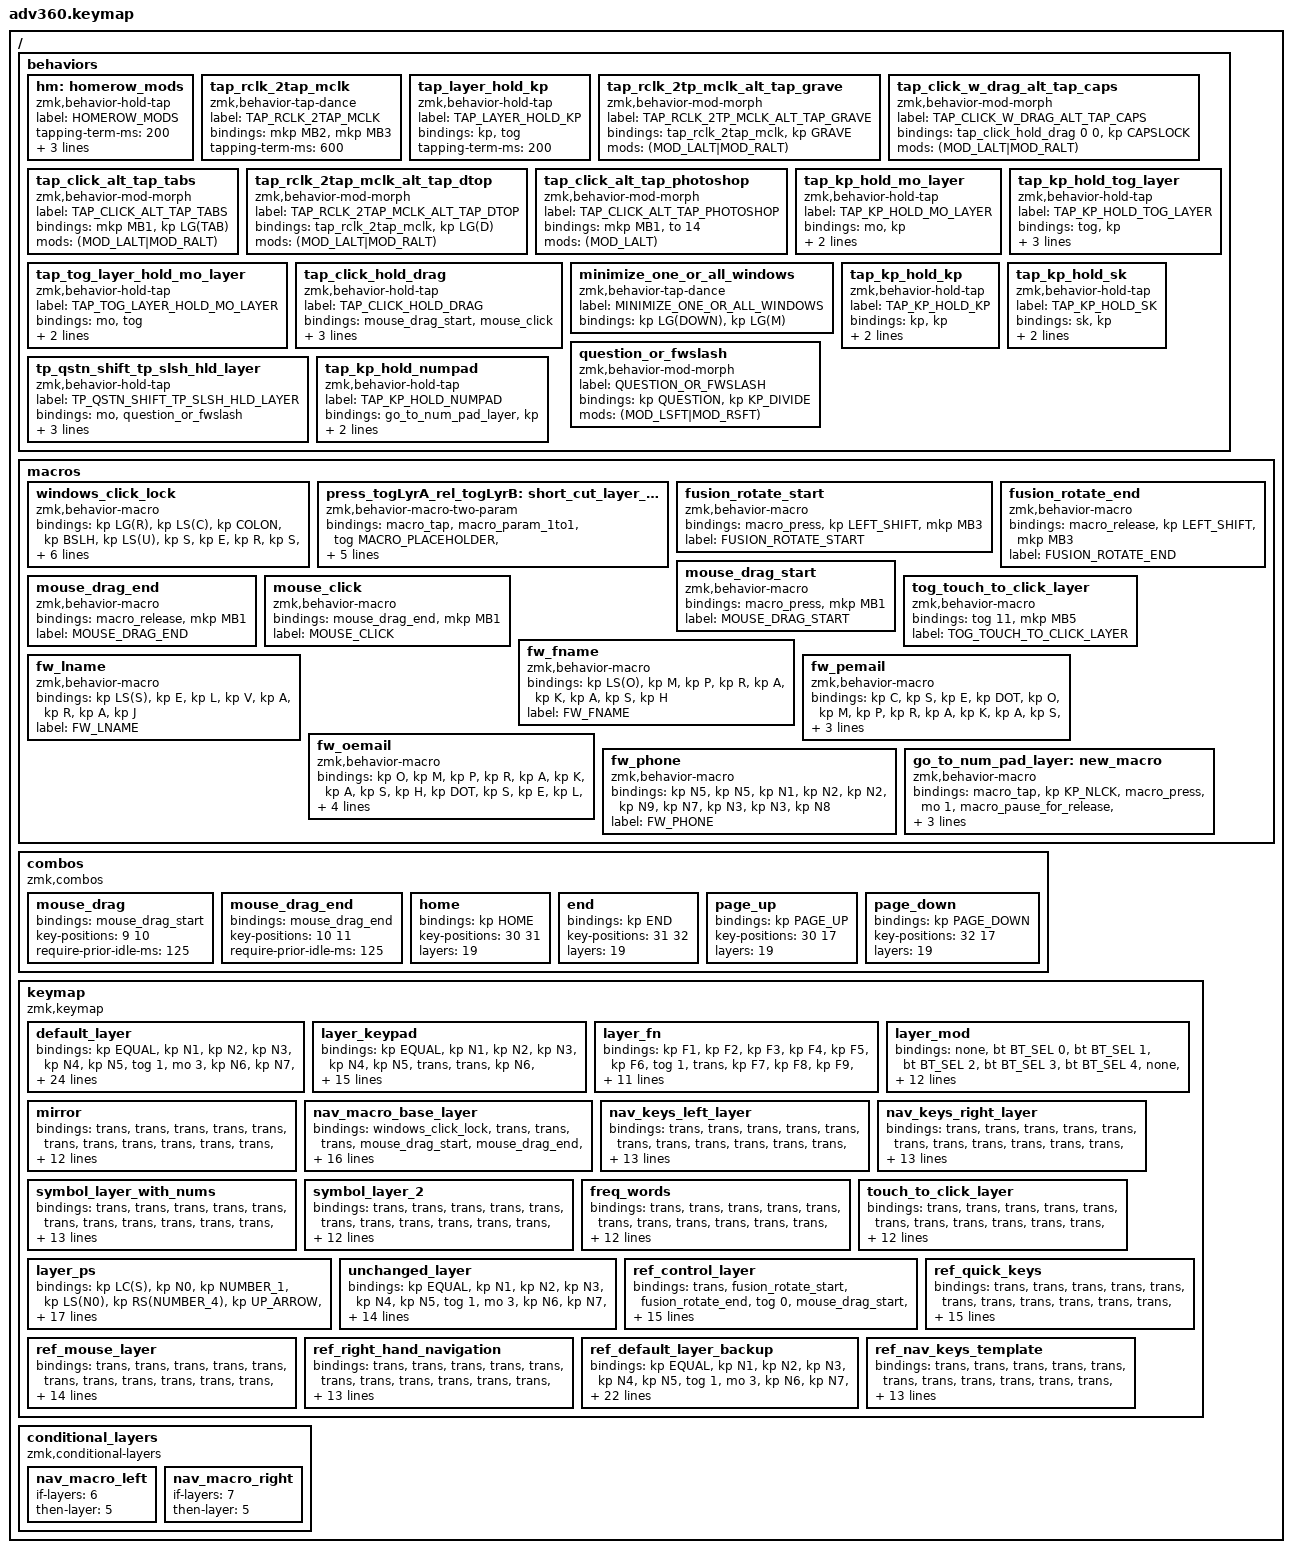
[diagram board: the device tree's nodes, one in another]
/*
 * Copyright (c) 2020 The ZMK Contributors
 *
 * SPDX-License-Identifier: MIT
 */
/* THIS FILE WAS GENERATED!
 *
 * This file was generated automatically. You may or may not want to
 * edit it directly.
 */

#include <dt-bindings/zmk/mouse.h>
#include <behaviors.dtsi>
#include <dt-bindings/zmk/backlight.h>
#include <dt-bindings/zmk/bt.h>
#include <dt-bindings/zmk/keys.h>
#include <dt-bindings/zmk/keys.h>
#include <dt-bindings/zmk/rgb.h>

/ {
    behaviors {
        #include "macros.dtsi"
    #include "version.dtsi"

        hm: homerow_mods {
            compatible = "zmk,behavior-hold-tap";
            label = "HOMEROW_MODS";
            #binding-cells = <2>;
            tapping-term-ms = <200>;
            quick_tap_ms = <175>;
            flavor = "tap-preferred";
            bindings = <&kp>, <&kp>;
        };

        tap_rclk_2tap_mclk: tap_rclk_2tap_mclk {
            compatible = "zmk,behavior-tap-dance";
            label = "TAP_RCLK_2TAP_MCLK";
            #binding-cells = <0>;
            bindings = <&mkp MB2>, <&mkp MB3>;

            tapping-term-ms = <600>;
        };

        tap_layer_hold_kp: tap_layer_hold_kp {
            compatible = "zmk,behavior-hold-tap";
            label = "TAP_LAYER_HOLD_KP";
            bindings = <&kp>, <&tog>;

            #binding-cells = <2>;
            tapping-term-ms = <200>;
        };

        tap_rclk_2tp_mclk_alt_tap_grave: tap_rclk_2tp_mclk_alt_tap_grave {
            compatible = "zmk,behavior-mod-morph";
            label = "TAP_RCLK_2TP_MCLK_ALT_TAP_GRAVE";
            bindings = <&tap_rclk_2tap_mclk>, <&kp GRAVE>;

            #binding-cells = <0>;
            mods = <(MOD_LALT|MOD_RALT)>;
        };

        tap_click_w_drag_alt_tap_caps: tap_click_w_drag_alt_tap_caps {
            compatible = "zmk,behavior-mod-morph";
            label = "TAP_CLICK_W_DRAG_ALT_TAP_CAPS";
            bindings = <&tap_click_hold_drag 0 0>, <&kp CAPSLOCK>;

            #binding-cells = <0>;
            mods = <(MOD_LALT|MOD_RALT)>;
        };

        tap_click_alt_tap_tabs: tap_click_alt_tap_tabs {
            compatible = "zmk,behavior-mod-morph";
            label = "TAP_CLICK_ALT_TAP_TABS";
            bindings = <&mkp MB1>, <&kp LG(TAB)>;

            #binding-cells = <0>;
            mods = <(MOD_LALT|MOD_RALT)>;
        };

        tap_rclk_2tap_mclk_alt_tap_dtop: tap_rclk_2tap_mclk_alt_tap_dtop {
            compatible = "zmk,behavior-mod-morph";
            label = "TAP_RCLK_2TAP_MCLK_ALT_TAP_DTOP";
            bindings = <&tap_rclk_2tap_mclk>, <&kp LG(D)>;

            #binding-cells = <0>;
            mods = <(MOD_LALT|MOD_RALT)>;
        };

        tap_click_alt_tap_photoshop: tap_click_alt_tap_photoshop {
            compatible = "zmk,behavior-mod-morph";
            label = "TAP_CLICK_ALT_TAP_PHOTOSHOP";
            bindings = <&mkp MB1>, <&to 14>;

            #binding-cells = <0>;
            mods = <(MOD_LALT)>;
        };

        tap_kp_hold_mo_layer: tap_kp_hold_mo_layer {
            compatible = "zmk,behavior-hold-tap";
            label = "TAP_KP_HOLD_MO_LAYER";
            bindings = <&mo>, <&kp>;

            #binding-cells = <2>;
            tapping-term-ms = <250>;
            flavor = "tap-preferred";
        };

        tap_kp_hold_tog_layer: tap_kp_hold_tog_layer {
            compatible = "zmk,behavior-hold-tap";
            label = "TAP_KP_HOLD_TOG_LAYER";
            bindings = <&tog>, <&kp>;

            #binding-cells = <2>;
            tapping-term-ms = <700>;
            flavor = "tap-preferred";
            require-prior-idle-ms = <125>;
        };

        tap_tog_layer_hold_mo_layer: tap_tog_layer_hold_mo_layer {
            compatible = "zmk,behavior-hold-tap";
            label = "TAP_TOG_LAYER_HOLD_MO_LAYER";
            bindings = <&mo>, <&tog>;

            #binding-cells = <2>;
            tapping-term-ms = <150>;
            flavor = "tap-preferred";
        };

        tap_click_hold_drag: tap_click_hold_drag {
            compatible = "zmk,behavior-hold-tap";
            label = "TAP_CLICK_HOLD_DRAG";
            bindings = <&mouse_drag_start>, <&mouse_click>;

            #binding-cells = <2>;
            tapping-term-ms = <200>;
            flavor = "tap-preferred";
            require-prior-idle-ms = <125>;
        };

        minimize_one_or_all_windows: minimize_one_or_all_windows {
            compatible = "zmk,behavior-tap-dance";
            label = "MINIMIZE_ONE_OR_ALL_WINDOWS";
            #binding-cells = <0>;
            bindings = <&kp LG(DOWN)>, <&kp LG(M)>;
        };

        tap_kp_hold_kp: tap_kp_hold_kp {
            compatible = "zmk,behavior-hold-tap";
            label = "TAP_KP_HOLD_KP";
            bindings = <&kp>, <&kp>;

            #binding-cells = <2>;
            tapping-term-ms = <250>;
            flavor = "tap-preferred";
        };

        tap_kp_hold_sk: tap_kp_hold_sk {
            compatible = "zmk,behavior-hold-tap";
            label = "TAP_KP_HOLD_SK";
            bindings = <&sk>, <&kp>;

            #binding-cells = <2>;
            tapping-term-ms = <350>;
            flavor = "tap-preferred";
        };

        question_or_fwslash: question_or_fwslash {
            compatible = "zmk,behavior-mod-morph";
            label = "QUESTION_OR_FWSLASH";
            bindings = <&kp QUESTION>, <&kp KP_DIVIDE>;

            #binding-cells = <0>;
            mods = <(MOD_LSFT|MOD_RSFT)>;
        };

        tp_qstn_shift_tp_slsh_hld_layer: tp_qstn_shift_tp_slsh_hld_layer {
            compatible = "zmk,behavior-hold-tap";
            label = "TP_QSTN_SHIFT_TP_SLSH_HLD_LAYER";
            bindings = <&mo>, <&question_or_fwslash>;

            #binding-cells = <2>;
            tapping-term-ms = <700>;
            flavor = "tap-preferred";
            require-prior-idle-ms = <125>;
        };

        tap_kp_hold_numpad: tap_kp_hold_numpad {
            compatible = "zmk,behavior-hold-tap";
            label = "TAP_KP_HOLD_NUMPAD";
            bindings = <&go_to_num_pad_layer>, <&kp>;

            #binding-cells = <2>;
            tapping-term-ms = <250>;
            flavor = "tap-preferred";
        };
    };

    macros {
        windows_click_lock: windows_click_lock {
            compatible = "zmk,behavior-macro";
            #binding-cells = <0>;
            bindings = <&kp LG(R) &kp LS(C) &kp COLON &kp BSLH &kp LS(U) &kp S &kp E &kp R &kp S &kp BSLH &kp O &kp M &kp P &kp R &kp A &kp BSLH &kp LS(D) &kp E &kp S &kp K &kp T &kp O &kp P &kp BSLH &kp C &kp L &kp I &kp C &kp K &kp L &kp O &kp C &kp K &kp DOT &kp V &kp B &kp S &kp ENTER>;
            label = "WINDOWS_CLICK_LOCK";
        };

        press_togLyrA_rel_togLyrB: short_cut_layer_activation {
            compatible = "zmk,behavior-macro-two-param";
            #binding-cells = <2>;
            bindings =
                <&macro_tap>,
                <&macro_param_1to1 &tog MACRO_PLACEHOLDER>,
                <&macro_pause_for_release>,
                <&macro_param_2to1 &tog MACRO_PLACEHOLDER>;

            label = "SHORT_CUT_LAYER_ACTIVATION";
            wait-ms = <1>;
            tap-ms = <1>;
        };

        fusion_rotate_start: fusion_rotate_start {
            compatible = "zmk,behavior-macro";
            #binding-cells = <0>;
            bindings = <&macro_press>, <&kp LEFT_SHIFT &mkp MB3>;

            label = "FUSION_ROTATE_START";
        };

        fusion_rotate_end: fusion_rotate_end {
            compatible = "zmk,behavior-macro";
            #binding-cells = <0>;
            bindings = <&macro_release>, <&kp LEFT_SHIFT &mkp MB3>;

            label = "FUSION_ROTATE_END";
        };

        mouse_drag_start: mouse_drag_start {
            compatible = "zmk,behavior-macro";
            #binding-cells = <0>;
            bindings = <&macro_press>, <&mkp MB1>;

            label = "MOUSE_DRAG_START";
        };

        mouse_drag_end: mouse_drag_end {
            compatible = "zmk,behavior-macro";
            #binding-cells = <0>;
            bindings = <&macro_release>, <&mkp MB1>;

            label = "MOUSE_DRAG_END";
        };

        mouse_click: mouse_click {
            compatible = "zmk,behavior-macro";
            #binding-cells = <0>;
            bindings = <&mouse_drag_end &mkp MB1>;
            label = "MOUSE_CLICK";
        };

        tog_touch_to_click_layer: tog_touch_to_click_layer {
            compatible = "zmk,behavior-macro";
            #binding-cells = <0>;
            bindings = <&tog 11 &mkp MB5>;
            label = "TOG_TOUCH_TO_CLICK_LAYER";
        };

        fw_fname: fw_fname {
            compatible = "zmk,behavior-macro";
            #binding-cells = <0>;
            bindings = <&kp LS(O) &kp M &kp P &kp R &kp A &kp K &kp A &kp S &kp H>;
            label = "FW_FNAME";
        };

        fw_lname: fw_lname {
            compatible = "zmk,behavior-macro";
            #binding-cells = <0>;
            bindings = <&kp LS(S) &kp E &kp L &kp V &kp A &kp R &kp A &kp J>;
            label = "FW_LNAME";
        };

        fw_pemail: fw_pemail {
            compatible = "zmk,behavior-macro";
            #binding-cells = <0>;
            bindings = <&kp C &kp S &kp E &kp DOT &kp O &kp M &kp P &kp R &kp A &kp K &kp A &kp S &kp H &kp AT &kp G &kp M &kp A &kp I &kp L &kp DOT &kp C &kp O &kp M>;
            label = "FW_PEMAIL";
        };

        fw_oemail: fw_oemail {
            compatible = "zmk,behavior-macro";
            #binding-cells = <0>;
            bindings = <&kp O &kp M &kp P &kp R &kp A &kp K &kp A &kp S &kp H &kp DOT &kp S &kp E &kp L &kp V &kp A &kp R &kp A &kp J &kp AT &kp B &kp N &kp Y &kp M &kp E &kp L &kp L &kp O &kp N &kp DOT &kp C &kp O &kp M>;
            label = "FW_OEMAIL";
        };

        fw_phone: fw_phone {
            compatible = "zmk,behavior-macro";
            #binding-cells = <0>;
            bindings = <&kp N5 &kp N5 &kp N1 &kp N2 &kp N2 &kp N9 &kp N7 &kp N3 &kp N3 &kp N8>;
            label = "FW_PHONE";
        };

        go_to_num_pad_layer: new_macro {
            compatible = "zmk,behavior-macro";
            #binding-cells = <0>;
            bindings =
                <&macro_tap>,
                <&kp KP_NLCK>,
                <&macro_press>,
                <&mo 1>,
                <&macro_pause_for_release>,
                <&macro_release>,
                <&mo 1>,
                <&macro_tap>,
                <&kp KP_NUMLOCK>;

            label = "NEW_MACRO";
        };
    };

    combos {
        compatible = "zmk,combos";

        mouse_drag {
            bindings = <&mouse_drag_start>;
            key-positions = <9 10>;
            require-prior-idle-ms = <125>;
        };

        mouse_drag_end {
            bindings = <&mouse_drag_end>;
            key-positions = <10 11>;
            require-prior-idle-ms = <125>;
        };

        home {
            bindings = <&kp HOME>;
            key-positions = <30 31>;
            layers = <19>;
        };

        end {
            bindings = <&kp END>;
            key-positions = <31 32>;
            layers = <19>;
        };

        page_up {
            bindings = <&kp PAGE_UP>;
            key-positions = <30 17>;
            layers = <19>;
        };

        page_down {
            bindings = <&kp PAGE_DOWN>;
            key-positions = <32 17>;
            layers = <19>;
        };
    };

    keymap {
        compatible = "zmk,keymap";

        default_layer {
            bindings = <
&kp EQUAL                          &kp N1                     &kp N2                     &kp N3                     &kp N4                      &kp N5                   &tog 1                                                                &mo 3          &kp N6                      &kp N7    &kp N8                     &kp N9                              &kp N0                          &kp MINUS
&kp ESCAPE                         &kp Q                      &kp W                      &kp E                      &kp R                       &kp T                    &mo 2                                                                 &tog 4         &kp Y                       &kp U     &kp I                      &kp O                               &kp SQT                         &kp BSLH
&kp TAB                            &tap_kp_hold_mo_layer 8 A  &kp S                      &tap_kp_hold_mo_layer 7 D  &kp F                       &kp G                    &tog 13    &kp LCTRL  &kp LALT           &kp LGUI  &kp RIGHT_CONTROL  &tog 12        &kp H                       &kp J     &tap_kp_hold_mo_layer 6 K  &kp L                               &tap_kp_hold_kp LC(LEFT_ALT) P  &kp SEMICOLON
&kp LEFT_SHIFT                     &question_or_fwslash       &tap_kp_hold_mo_layer 9 Z  &tap_kp_hold_mo_layer 6 X  &tap_kp_hold_mo_layer 10 C  &tap_kp_hold_numpad 0 V                        &kp PAGE_UP        &kp HOME                                    &tap_kp_hold_kp LEFT_GUI B  &kp N     &tap_kp_hold_mo_layer 7 M  &tap_kp_hold_kp LEFT_CONTROL COMMA  &kp DOT                         &kp RIGHT_SHIFT
&tap_layer_hold_kp LEFT_CONTROL 6  &kp GRAVE                  &kp UP_ARROW               &kp CLCK                   &kp DOWN                                             &kp SPACE  &kp ENTER  &kp PAGE_DOWN      &kp END   &kp DEL            &kp BACKSPACE                              &kp LEFT  &kp LEFT_BRACKET           &kp RIGHT                           &kp RBKT                        &tap_layer_hold_kp RIGHT_CONTROL 7
            >;
        };

        layer_keypad {
            bindings = <
&kp EQUAL  &kp N1     &kp N2    &kp N3    &kp N4     &kp N5  &trans                                                   &trans     &kp N6  &kp KP_NUM  &kp KP_EQUAL  &kp KP_DIVIDE  &kp KP_MULTIPLY  &kp MINUS
&kp TAB    &kp Q      &kp W     &kp E     &kp R      &kp T   &none                                                    &none      &kp Y   &kp KP_N7   &kp KP_N8     &kp KP_N9      &kp KP_MINUS     &kp BSLH
&kp ESC    &kp A      &kp S     &kp D     &kp F      &kp G   &none     &kp LCTRL  &kp LALT      &kp LGUI   &kp RCTRL  &none      &kp H   &kp KP_N4   &kp KP_N5     &kp KP_N6      &kp KP_PLUS      &kp SQT
&kp LSHFT  &kp Z      &kp X     &kp C     &kp V      &kp B                        &kp HOME      &kp PG_UP                        &kp N   &kp KP_N1   &kp KP_N2     &kp KP_N3      &kp KP_ENTER     &kp RSHFT
&mo 3      &kp GRAVE  &kp CAPS  &kp LEFT  &kp RIGHT          &kp BSPC  &kp DEL    &kp END       &kp PG_DN  &kp ENTER  &kp KP_N0          &kp UP      &kp KP_N0     &kp KP_DOT     &kp RBKT         &mo 3
            >;
        };

        layer_fn {
            bindings = <
&kp F1  &kp F2  &kp F3  &kp F4  &kp F5  &kp F6  &tog 1                                      &trans  &kp F7  &kp F8  &kp F9  &kp F10  &kp F11  &kp F12
&trans  &trans  &trans  &trans  &trans  &trans  &none                                       &none   &trans  &trans  &trans  &trans   &trans   &trans
&trans  &trans  &trans  &trans  &trans  &trans  &none   &trans  &trans      &trans  &trans  &trans  &trans  &trans  &trans  &trans   &trans   &trans
&trans  &trans  &trans  &trans  &trans  &trans                  &trans      &trans                  &trans  &trans  &trans  &trans   &trans   &trans
&trans  &trans  &trans  &trans  &trans          &trans  &trans  &trans      &trans  &trans  &trans          &trans  &trans  &trans   &trans   &trans
            >;
        };

        layer_mod {
            bindings = <
&none  &bt BT_SEL 0  &bt BT_SEL 1  &bt BT_SEL 2  &bt BT_SEL 3  &bt BT_SEL 4  &none                                                  &trans                  &none  &none       &none       &none  &none  &none
&none  &none         &none         &none         &none         &none         &bootloader                                            &bootloader             &none  &none       &none       &none  &none  &none
&none  &none         &none         &none         &none         &none         &none        &none  &none      &bt BT_CLR  &none       &rgb_ug RGB_MEFS_CMD 5  &none  &none       &none       &none  &none  &none
&none  &none         &none         &none         &macro_ver    &none                             &none      &none                                           &none  &none       &none       &none  &none  &none
&none  &none         &none         &none         &none                       &none        &none  &none      &none       &bl BL_TOG  &rgb_ug RGB_TOG                &bl BL_INC  &bl BL_DEC  &none  &none  &none
            >;
        };

        mirror {
            bindings = <
&trans  &trans  &trans  &trans  &trans  &trans  &trans                                                 &trans     &trans  &trans  &trans  &trans  &trans  &trans
&trans  &trans  &trans  &trans  &trans  &trans  &trans                                                 &trans     &trans  &trans  &trans  &trans  &trans  &trans
&trans  &trans  &trans  &trans  &trans  &trans  &trans         &trans   &trans      &trans  &trans     &trans     &trans  &trans  &trans  &trans  &trans  &trans
&trans  &trans  &trans  &trans  &trans  &trans                          &trans      &trans                        &trans  &trans  &trans  &trans  &trans  &trans
&trans  &trans  &trans  &trans  &trans          &kp BACKSPACE  &kp DEL  &trans      &trans  &kp ENTER  &kp SPACE          &trans  &trans  &trans  &trans  &trans
            >;
        };

        nav_macro_base_layer {
            bindings = <
&windows_click_lock  &trans    &trans         &trans  &mouse_drag_start  &mouse_drag_end  &kp C_MUTE                                             &trans  &mouse_drag_end  &mouse_drag_start             &trans  &trans      &trans   &trans
&trans               &trans    &trans         &trans  &trans             &trans           &kp C_VOLUME_UP                                        &trans  &trans           &kp LG(UP_ARROW)              &trans  &kp LA(F4)  &trans   &trans
&trans               &kp HOME  &kp BACKSPACE  &trans  &kp ENTER          &kp END          &kp C_VOLUME_DOWN  &trans  &trans      &trans  &trans  &trans  &kp HOME         &kp BACKSPACE                 &trans  &kp ENTER   &kp END  &tog_touch_to_click_layer
&trans               &trans    &trans         &trans  &trans             &trans                                      &trans      &trans                  &trans           &minimize_one_or_all_windows  &trans  &kp LCMD    &trans   &trans
&trans               &trans    &trans         &trans  &trans                              &trans             &trans  &trans      &trans  &trans  &trans                   &trans                        &trans  &trans      &trans   &trans
            >;
        };

        nav_keys_left_layer {
            bindings = <
&trans  &trans  &trans            &trans        &trans        &trans                          &trans                                      &trans  &trans  &trans  &trans  &trans  &trans  &trans
&trans  &trans  &kp LC(UP_ARROW)  &kp UP_ARROW  &kp LC(DOWN)  &press_togLyrA_rel_togLyrB 6 6  &trans                                      &trans  &trans  &trans  &trans  &trans  &trans  &trans
&trans  &trans  &kp LEFT          &kp DOWN      &kp RIGHT     &trans                          &trans  &trans  &trans      &trans  &trans  &trans  &trans  &trans  &trans  &trans  &trans  &trans
&trans  &trans  &kp LC(Z)         &kp LC(X)     &kp LC(C)     &kp LC(V)                                       &trans      &trans                  &trans  &trans  &trans  &trans  &trans  &trans
&trans  &trans  &kp LC(Y)         &trans        &trans                                        &trans  &trans  &trans      &trans  &trans  &trans          &trans  &trans  &trans  &trans  &trans
            >;
        };

        nav_keys_right_layer {
            bindings = <
&trans  &trans  &trans  &trans  &trans  &trans  &trans                                      &trans  &trans                          &trans            &trans        &trans        &trans  &trans
&trans  &trans  &trans  &trans  &trans  &trans  &trans                                      &trans  &press_togLyrA_rel_togLyrB 7 7  &kp LC(UP_ARROW)  &kp UP_ARROW  &kp LC(DOWN)  &trans  &trans
&trans  &trans  &trans  &trans  &trans  &trans  &trans  &trans  &trans      &trans  &trans  &trans  &trans                          &kp LEFT          &kp DOWN      &kp RIGHT     &trans  &trans
&trans  &trans  &trans  &trans  &trans  &trans                  &trans      &trans                  &kp LC(V)                       &kp LC(C)         &kp LC(X)     &kp LC(Z)     &trans  &trans
&trans  &trans  &trans  &trans  &trans          &trans  &trans  &trans      &trans  &trans  &trans                                  &trans            &trans        &kp LC(Y)     &trans  &trans
            >;
        };

        symbol_layer_with_nums {
            bindings = <
&trans  &trans  &trans  &trans  &trans  &trans  &trans                                      &trans         &trans     &trans                &trans                 &trans             &trans            &trans
&trans  &trans  &kp N7  &kp N8  &kp N9  &trans  &trans                                      &trans         &kp LBKT   &kp RBKT              &kp LEFT_BRACE         &kp RIGHT_BRACE    &trans            &trans
&trans  &trans  &kp N4  &kp N5  &kp N6  &kp N0  &trans  &trans  &trans      &trans  &trans  &trans         &kp PLUS   &kp LEFT_PARENTHESIS  &kp RIGHT_PARENTHESIS  &kp DOUBLE_QUOTES  &kp SINGLE_QUOTE  &trans
&trans  &trans  &kp N1  &kp N2  &kp N3  &kp N0                  &trans      &trans                         &kp MINUS  &kp EQUAL             &kp UNDER              &trans             &trans            &trans
&trans  &trans  &trans  &kp N0  &trans          &trans  &trans  &trans      &trans  &trans  &kp SEMICOLON             &trans                &trans                 &trans             &trans            &trans
            >;
        };

        symbol_layer_2 {
            bindings = <
&trans  &trans  &trans  &trans  &trans  &trans  &trans                                      &trans  &trans     &trans      &trans      &trans      &trans    &trans
&trans  &trans  &trans  &trans  &trans  &trans  &trans                                      &trans  &kp FSLH   &kp LS(N7)  &kp LS(N8)  &kp LS(N9)  &kp BSLH  &trans
&trans  &trans  &trans  &trans  &trans  &trans  &trans  &trans  &trans      &trans  &trans  &trans  &kp TILDE  &kp LS(N4)  &kp LS(N5)  &kp LS(N6)  &kp PIPE  &trans
&trans  &trans  &trans  &trans  &trans  &trans                  &trans      &trans                  &kp GRAVE  &kp LS(N1)  &kp LS(N2)  &kp LS(N3)  &trans    &trans
&trans  &trans  &trans  &trans  &trans          &trans  &trans  &trans      &trans  &trans  &trans             &trans      &kp LS(N0)  &trans      &trans    &trans
            >;
        };

        freq_words {
            bindings = <
&trans  &trans  &trans  &trans  &trans  &trans  &trans                                      &trans  &trans  &trans     &trans     &trans      &trans     &trans
&trans  &trans  &trans  &trans  &trans  &trans  &trans                                      &trans  &trans  &trans     &trans     &fw_oemail  &trans     &trans
&trans  &trans  &trans  &trans  &trans  &trans  &trans  &trans  &trans      &trans  &trans  &trans  &trans  &fw_fname  &fw_lname  &fw_pemail  &fw_phone  &trans
&trans  &trans  &trans  &trans  &trans  &trans                  &trans      &trans                  &trans  &trans     &trans     &trans      &trans     &trans
&trans  &trans  &trans  &trans  &trans          &trans  &trans  &trans      &trans  &trans  &trans          &trans     &trans     &trans      &trans     &trans
            >;
        };

        touch_to_click_layer {
            bindings = <
&trans  &trans  &trans  &trans  &trans  &trans  &trans                                      &trans  &trans  &trans  &trans  &trans  &trans  &trans
&trans  &trans  &trans  &trans  &trans  &trans  &trans                                      &trans  &trans  &trans  &trans  &trans  &trans  &trans
&trans  &trans  &trans  &trans  &trans  &trans  &trans  &trans  &trans      &trans  &trans  &trans  &trans  &trans  &trans  &trans  &trans  &tog_touch_to_click_layer
&trans  &trans  &trans  &trans  &trans  &trans                  &trans      &trans                  &trans  &trans  &trans  &trans  &trans  &trans
&trans  &trans  &trans  &trans  &trans          &trans  &trans  &trans      &trans  &trans  &trans          &trans  &trans  &trans  &trans  &trans
            >;
        };

        layer_ps {
            bindings = <
&kp LC(S)       &kp N0                &kp NUMBER_1   &kp LS(N0)         &kp RS(NUMBER_4)   &kp UP_ARROW    &kp LC(T)                                                        &trans  &trans  &trans  &trans  &trans             &trans  &trans
&kp LC(A)       &kp LC(D)             &kp LC(I)      &kp LS(LA(LC(E)))  &kp LEFT_ARROW     &kp DOWN_ARROW  &kp RIGHT                                                        &trans  &trans  &trans  &trans  &kp LS(LA(LC(W)))  &trans  &trans
&kp ESCAPE      &kp X                 &kp D          &kp LEFT_BRACKET   &kp RIGHT_BRACKET  &kp LC(J)       &kp LC(LS(N))  &kp LCTRL  &kp LEFT_ALT           &trans  &trans  &to 0   &trans  &trans  &trans  &trans             &trans  &trans
&kp LEFT_SHIFT  &kp NON_US_BACKSLASH  &kp LC(Z)      &kp LC(X)          &kp LC(C)          &kp LC(V)                                 &kp LC(LA(LS(G)))      &trans                  &trans  &trans  &trans  &trans             &trans  &trans
&kp B           &kp TILDE             &kp LC(LS(Z))  &kp MINUS          &kp PLUS                           &kp SPACE      &kp ENTER  &kp DEL                &trans  &trans  &trans          &trans  &trans  &trans             &trans  &trans
            >;
        };

        unchanged_layer {
            bindings = <
&kp EQUAL   &kp N1     &kp N2        &kp N3    &kp N4    &kp N5  &tog 1                                                             &mo 3     &kp N6  &kp N7    &kp N8            &kp N9     &kp N0    &kp MINUS
&kp ESCAPE  &kp Q      &kp W         &kp E     &kp R     &kp T   &kp SCROLLLOCK                                                     &trans    &kp Y   &kp U     &kp I             &kp O      &kp SQT   &kp BSLH
&kp TAB     &kp A      &kp S         &kp D     &kp F     &kp G   &trans          &kp LCTRL  &kp LALT           &kp LGUI  &kp RCTRL  &trans    &kp H   &kp J     &kp K             &kp L      &kp P     &kp SEMICOLON
&kp LSHFT   &kp SLASH  &kp Z         &kp X     &kp C     &kp V                              &kp PAGE_UP        &kp HOME                       &kp B   &kp N     &kp M             &kp COMMA  &kp DOT   &kp RSHFT
&mo 2       &kp GRAVE  &kp UP_ARROW  &kp CAPS  &kp DOWN          &kp SPACE       &kp ENTER  &kp PAGE_DOWN      &kp END   &kp DEL    &kp BSPC          &kp LEFT  &kp LEFT_BRACKET  &kp RIGHT  &kp RBKT  &mo 2
            >;
        };

        ref_control_layer {
            bindings = <
&trans  &fusion_rotate_start  &fusion_rotate_end  &tog 0     &mouse_drag_start  &mouse_drag_end  &trans                                      &trans  &trans    &trans     &trans  &trans          &trans           &trans
&trans  &trans                &trans              &trans     &kp SCROLLLOCK     &kp UP_ARROW     &trans                                      &trans  &kp UP    &kp LC(Y)  &trans  &kp LC(O)       &trans           &trans
&trans  &kp LC(A)             &kp LC(S)           &kp LC(D)  &trans             &kp DOWN         &trans  &trans  &trans      &trans  &trans  &trans  &kp DOWN  &trans     &trans  &trans          &kp PRINTSCREEN  &trans
&trans  &windows_click_lock   &kp LC(Z)           &kp LC(X)  &kp LC(C)          &kp LC(V)                        &trans      &trans                  &trans    &trans     &trans  &trans          &kp UP_ARROW     &trans
&trans  &trans                &kp LC(UP_ARROW)    &trans     &kp LC(DOWN)                        &trans  &trans  &trans      &trans  &trans  &trans            &trans     &trans  &kp LEFT_ARROW  &kp DOWN         &kp RIGHT
            >;
        };

        ref_quick_keys {
            bindings = <
&trans  &trans     &trans            &trans        &trans        &trans                            &trans                                      &trans                     &trans    &trans         &trans   &trans     &trans   &trans
&trans  &tog 16    &kp LC(UP_ARROW)  &kp UP_ARROW  &kp LC(DOWN)  &trans                            &trans                                      &trans                     &trans    &trans         &trans   &trans     &trans   &trans
&trans  &kp LC(A)  &kp LEFT          &kp DOWN      &kp RIGHT     &press_togLyrA_rel_togLyrB 16 16  &trans  &trans  &trans      &trans  &trans  &trans                     &kp HOME  &kp BACKSPACE  &tog 16  &kp ENTER  &kp END  &trans
&trans  &kp LC(Y)  &kp LC(Z)         &kp LC(X)     &kp LC(C)     &kp LC(V)                                         &trans      &trans                                     &trans    &trans         &trans   &trans     &trans   &trans
&trans  &trans     &trans            &trans        &trans                                          &trans  &trans  &trans      &trans  &trans  &tog_touch_to_click_layer            &trans         &trans   &trans     &trans   &trans
            >;
        };

        ref_mouse_layer {
            bindings = <
&trans  &trans   &trans    &trans        &trans     &trans  &trans                                      &trans  &trans     &trans        &trans     &trans     &trans               &trans
&trans  &tog 17  &trans    &kp UP_ARROW  &trans     &trans  &trans                                      &trans  &trans     &trans        &tog 17    &trans     &trans               &trans
&trans  &trans   &kp LEFT  &kp DOWN      &kp RIGHT  &trans  &trans  &trans  &trans      &trans  &trans  &trans  &kp LC(A)  &kp UP_ARROW  &mkp MB1   &kp DOWN   &tap_rclk_2tap_mclk  &kp ENTER
&trans  &trans   &trans    &trans        &trans     &trans                  &trans      &trans                  &kp LC(Y)  &kp LC(X)     &kp LC(C)  &kp LC(V)  &kp LC(Z)            &tap_tog_layer_hold_mo_layer 17 17
&trans  &trans   &trans    &trans        &trans             &trans  &trans  &trans      &trans  &trans  &trans             &trans        &trans     &trans     &trans               &trans
            >;
        };

        ref_right_hand_navigation {
            bindings = <
&trans  &trans  &trans  &trans  &trans  &trans  &trans                                      &trans  &trans  &trans            &trans        &trans        &trans  &trans
&trans  &trans  &trans  &trans  &trans  &trans  &trans                                      &trans  &trans  &kp LC(UP_ARROW)  &kp UP_ARROW  &kp LC(DOWN)  &trans  &trans
&trans  &trans  &trans  &trans  &trans  &trans  &trans  &trans  &trans      &trans  &trans  &trans  &trans  &kp LEFT          &kp DOWN      &kp RIGHT     &trans  &trans
&trans  &trans  &trans  &trans  &trans  &trans                  &trans      &trans                  &trans  &trans            &trans        &trans        &trans  &tap_layer_hold_kp LEFT_SHIFT 17
&trans  &trans  &trans  &trans  &trans          &trans  &trans  &trans      &trans  &trans  &trans          &trans            &trans        &trans        &trans  &trans
            >;
        };

        ref_default_layer_backup {
            bindings = <
&kp EQUAL                           &kp N1                            &kp N2        &kp N3                          &kp N4    &kp N5  &tog 1                                                                                      &mo 3                               &kp N6  &kp N7    &kp N8                       &kp N9     &kp N0    &kp MINUS
&kp ESCAPE                          &kp Q                             &kp W         &kp E                           &kp R     &kp T   &tap_rclk_2tap_mclk_alt_tap_dtop                                                            &tap_rclk_2tap_mclk                 &kp Y   &kp U     &tap_kp_hold_tog_layer 17 I  &kp O      &kp SQT   &kp BSLH
&kp TAB                             &kp A                             &kp S         &kp D                           &kp F     &kp G   &tap_click_alt_tap_tabs           &kp LCTRL  &kp LALT           &kp LGUI  &sk LEFT_CONTROL  &tap_click_alt_tap_photoshop        &kp H   &kp J     &tap_kp_hold_mo_layer 16 K   &kp L      &kp P     &kp SEMICOLON
&tap_layer_hold_kp LEFT_SHIFT 4     &kp SLASH                         &kp Z         &kp X                           &kp C     &kp V                                                &kp PAGE_UP        &kp HOME                                                        &kp B   &kp N     &tap_kp_hold_tog_layer 17 M  &kp COMMA  &kp DOT   &kt RIGHT_SHIFT
&tap_layer_hold_kp LEFT_CONTROL 16  &tap_rclk_2tp_mclk_alt_tap_grave  &kp UP_ARROW  &tap_click_w_drag_alt_tap_caps  &kp DOWN          &kp SPACE                         &kp ENTER  &kp PAGE_DOWN      &kp END   &kp DEL           &tap_kp_hold_mo_layer 17 BACKSPACE          &kp LEFT  &kp LEFT_BRACKET             &kp RIGHT  &kp RBKT  &mo 2
            >;
        };

        ref_nav_keys_template {
            bindings = <
&trans  &trans     &trans            &trans        &trans        &trans     &trans                                      &trans  &trans     &trans            &trans        &trans        &trans     &trans
&trans  &trans     &kp LC(UP_ARROW)  &kp UP_ARROW  &kp LC(DOWN)  &trans     &trans                                      &trans  &trans     &kp LC(UP_ARROW)  &kp UP_ARROW  &kp LC(DOWN)  &trans     &trans
&trans  &kp LC(A)  &kp LEFT          &kp DOWN      &kp RIGHT     &trans     &trans  &trans  &trans      &trans  &trans  &trans  &kp LC(A)  &kp LEFT          &kp DOWN      &kp RIGHT     &trans     &trans
&trans  &kp LC(Y)  &kp LC(Z)         &kp LC(X)     &kp LC(C)     &kp LC(V)                  &trans      &trans                  &kp LC(Y)  &kp LC(Z)         &kp LC(X)     &kp LC(C)     &kp LC(V)  &trans
&trans  &trans     &trans            &trans        &trans                   &trans  &trans  &trans      &trans  &trans  &trans             &trans            &trans        &trans        &trans     &trans
            >;
        };
    };

    conditional_layers {
        compatible = "zmk,conditional-layers";

        nav_macro_left {
            if-layers = <6>;
            then-layer = <5>;
        };

        nav_macro_right {
            if-layers = <7>;
            then-layer = <5>;
        };
    };
};
